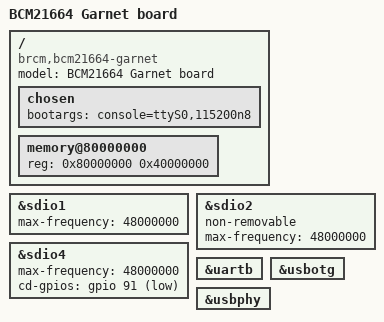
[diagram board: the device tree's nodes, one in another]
// SPDX-License-Identifier: GPL-2.0-only
// Copyright (C) 2014 Broadcom Corporation

/dts-v1/;

#include <dt-bindings/gpio/gpio.h>

#include "bcm21664.dtsi"

/ {
	model = "BCM21664 Garnet board";
	compatible = "brcm,bcm21664-garnet", "brcm,bcm21664";

	chosen {
		bootargs = "console=ttyS0,115200n8";
	};

	memory@80000000 {
		device_type = "memory";
		reg = <0x80000000 0x40000000>; /* 1 GB */
	};
};

&sdio1 {
	max-frequency = <48000000>;
	status = "okay";
};

&sdio2 {
	non-removable;
	max-frequency = <48000000>;
	status = "okay";
};

&sdio4 {
	max-frequency = <48000000>;
	cd-gpios = <&gpio 91 GPIO_ACTIVE_LOW>;
	status = "okay";
};

&uartb {
	status = "okay";
};

&usbotg {
	status = "okay";
};

&usbphy {
	status = "okay";
};
